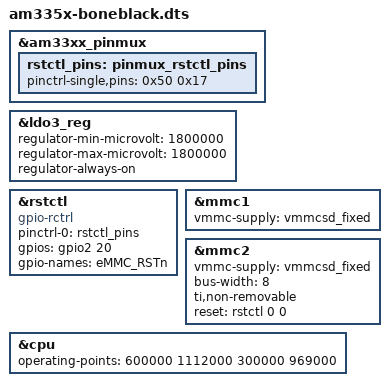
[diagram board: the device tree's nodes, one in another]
/*
 * Copyright (C) 2012 Texas Instruments Incorporated - http://www.ti.com/
 *
 * This program is free software; you can redistribute it and/or modify
 * it under the terms of the GNU General Public License version 2 as
 * published by the Free Software Foundation.
 */
/dts-v1/;

/include/ "am33xx.dtsi"

/include/ "am335x-bone-common.dtsi"

/* begin srs adds */

/* loading the ADC firmware here causes the sysfs helper interfaces
 * not to be installed (the raw sysfs interfaces do get installed ok).
 * Others have reported this same problem. Looks like
 * the ADC driver isn't installed before the helper tries to access the
 * channels, so the helper bails and doesn't create the sysfs interfaces.
 * The raw input interfaces get installed by the ADC driver ok.
 * I'll leave this here in case we get a chance to come back and see
 * if there is a way to force the driver to load first. Or we could just
 * hack the bone-iio-helper_probe function in bone-iio-helper.c to
 * ignore the error and install the sysfs interfaces anyway.
 */

/* -- begin removed --
/ {
	bone_capemgr {
		slots {
			slot@103 {
				ti,cape-override;
				priority = <1>;
				compatible = "ti,beaglebone-black";
				board-name = "Bone-Black-ADC";
				version = "00A0";
				manufacturer = "Texas Instruments";
				part-number = "BB-ADC";
			};
		};
	};
};
 -- end removed -- */
/* end srs adds */

&am33xx_pinmux {
	rstctl_pins: pinmux_rstctl_pins {
		pinctrl-single,pins = <
			/* eMMC_RSTn */
			0x50 0x17	/* gpmc_a4.gpio1_20, OUTPUT | MODE7 | PULLUP */
		>;
	};
};

&ldo3_reg {
	regulator-min-microvolt = <1800000>;
	regulator-max-microvolt = <1800000>;
	regulator-always-on;
};

&rstctl {
	status = "okay";
	compatible = "gpio-rctrl";
	pinctrl-names = "default";
	pinctrl-0 = <&rstctl_pins>;

	#reset-cells = <2>;

	gpios = <&gpio2 20 0x00>;
	gpio-names = "eMMC_RSTn";
};

&mmc1 {
	vmmc-supply = <&vmmcsd_fixed>;
};

&mmc2 {
	vmmc-supply = <&vmmcsd_fixed>;
	bus-width = <8>;
	ti,non-removable;
	status = "okay";	/* nriedel was "disabled" */

	reset = <&rstctl 0 0>;
	reset-names = "eMMC_RSTn-CONSUMER";
};


&cpu {
	/*
	 * To consider voltage drop between PMIC and SoC,
	 * tolerance value is reduced to 2% from 4% and
	 * voltage value is increased as a precaution.
	 */
	operating-points = <
		/* kHz    uV */
	/*	1000000	1350000	nriedel remove 1GHz and 800MHz for IP Keys
		800000	1300000 */
		600000  1112000
		300000   969000
	>;
};
